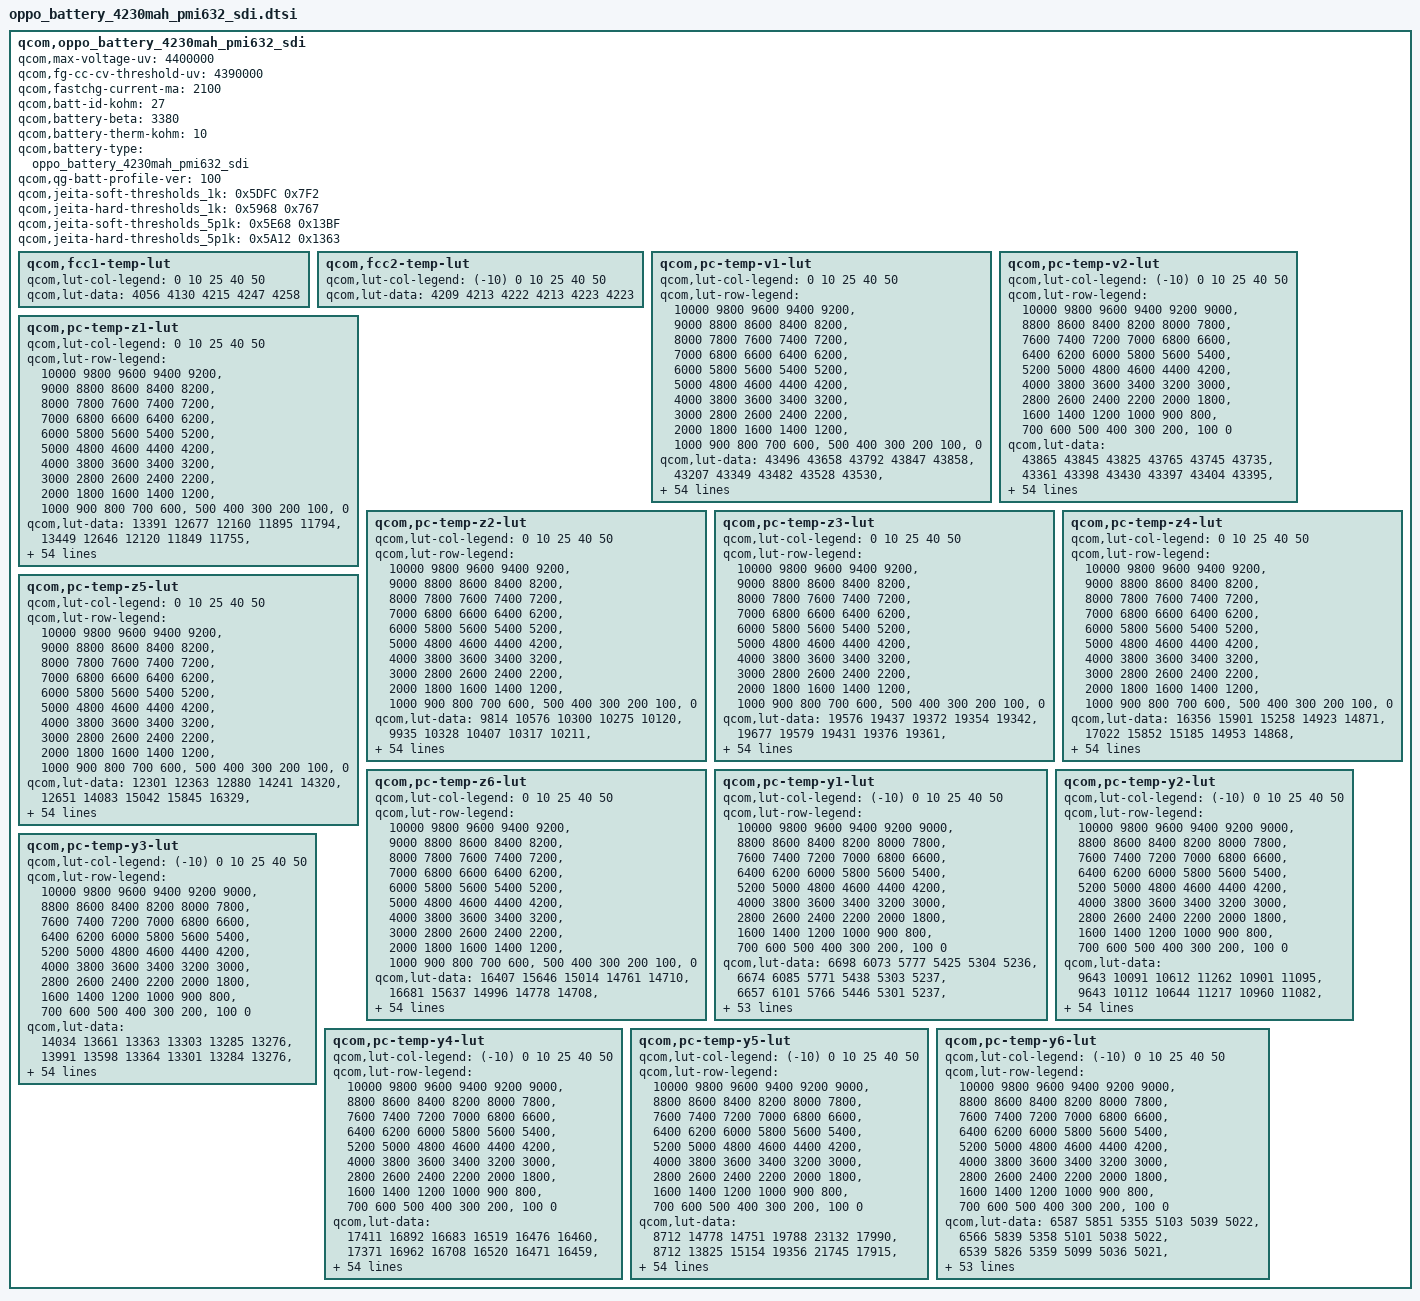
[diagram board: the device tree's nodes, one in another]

qcom,oppo_battery_4230mah_pmi632_sdi {
    qcom,max-voltage-uv = <4400000>;
    qcom,fg-cc-cv-threshold-uv = <4390000>;
    qcom,fastchg-current-ma = <2100>;
    qcom,batt-id-kohm = <27>;
    qcom,battery-beta = <3380>;
    qcom,battery-therm-kohm = <10>;
    qcom,battery-type = "oppo_battery_4230mah_pmi632_sdi";
    qcom,qg-batt-profile-ver = <100>;
    qcom,jeita-soft-thresholds_1k = <0x5DFC 0x7F2>;      //soft threshold -30  90
    qcom,jeita-hard-thresholds_1k = <0x5968 0x767>;      //hard threshold -35  95
    qcom,jeita-soft-thresholds_5p1k = <0x5E68 0x13BF>;   //soft threshold -30  90
    qcom,jeita-hard-thresholds_5p1k = <0x5A12 0x1363>;   //hard threshold -35  95

	qcom,fcc1-temp-lut {
		qcom,lut-col-legend = <0 10 25 40 50>;
		qcom,lut-data = <4056 4130 4215 4247 4258>;
	};

	qcom,fcc2-temp-lut {
		qcom,lut-col-legend = <(-10) 0 10 25 40 50>;
		qcom,lut-data = <4209 4213 4222 4213 4223 4223>;
	};

	qcom,pc-temp-v1-lut {
		qcom,lut-col-legend = <0 10 25 40 50>;
		qcom,lut-row-legend = <10000 9800 9600 9400 9200>,
			<9000 8800 8600 8400 8200>,
			<8000 7800 7600 7400 7200>,
			<7000 6800 6600 6400 6200>,
			<6000 5800 5600 5400 5200>,
			<5000 4800 4600 4400 4200>,
			<4000 3800 3600 3400 3200>,
			<3000 2800 2600 2400 2200>,
			<2000 1800 1600 1400 1200>,
			<1000 900 800 700 600>,
			<500 400 300 200 100>,
			<0>;
		qcom,lut-data = <43496 43658 43792 43847 43858>,
			<43207 43349 43482 43528 43530>,
			<42943 43079 43194 43240 43246>,
			<42695 42837 42932 42977 42983>,
			<42459 42605 42691 42738 42742>,
			<42234 42371 42458 42509 42512>,
			<42014 42143 42231 42275 42282>,
			<41799 41922 42008 42043 42054>,
			<41594 41705 41782 41816 41830>,
			<41403 41496 41554 41593 41605>,
			<41227 41305 41336 41375 41384>,
			<41036 41122 41136 41165 41170>,
			<40805 40922 40942 40962 40962>,
			<40561 40695 40739 40761 40760>,
			<40339 40468 40528 40559 40561>,
			<40130 40265 40329 40365 40369>,
			<39949 40074 40145 40183 40188>,
			<39811 39914 39974 40011 40015>,
			<39695 39788 39822 39848 39851>,
			<39577 39671 39686 39700 39700>,
			<39456 39541 39542 39548 39547>,
			<39337 39404 39377 39376 39375>,
			<39215 39246 39200 39193 39193>,
			<39092 39023 39008 39011 39013>,
			<38972 38791 38792 38820 38828>,
			<38855 38644 38632 38657 38664>,
			<38741 38539 38544 38549 38544>,
			<38632 38463 38476 38462 38445>,
			<38520 38410 38408 38379 38357>,
			<38428 38369 38342 38297 38278>,
			<38368 38331 38282 38224 38208>,
			<38321 38297 38226 38160 38142>,
			<38284 38265 38174 38105 38081>,
			<38254 38233 38129 38055 38026>,
			<38228 38204 38091 38012 37978>,
			<38202 38174 38053 37970 37929>,
			<38177 38145 38016 37925 37876>,
			<38145 38111 37977 37877 37818>,
			<38099 38057 37922 37814 37748>,
			<38035 37974 37844 37732 37660>,
			<37949 37877 37752 37636 37561>,
			<37820 37760 37641 37529 37452>,
			<37680 37623 37510 37403 37326>,
			<37531 37456 37347 37242 37164>,
			<37386 37299 37190 37092 37020>,
			<37270 37181 37077 36989 36926>,
			<37225 37143 37051 36957 36901>,
			<37191 37122 37027 36940 36879>,
			<37163 37098 37013 36921 36862>,
			<37121 37079 36981 36887 36824>,
			<36984 36940 36814 36700 36609>,
			<36576 36529 36397 36285 36188>,
			<36007 35959 35832 35723 35625>,
			<35241 35195 35061 34958 34857>,
			<34027 34002 33855 33774 33672>,
			<30000 30000 30000 30000 30000>;
	};

	qcom,pc-temp-v2-lut {
		qcom,lut-col-legend = <(-10) 0 10 25 40 50>;
		qcom,lut-row-legend = <10000 9800 9600 9400 9200 9000>,
			<8800 8600 8400 8200 8000 7800>,
			<7600 7400 7200 7000 6800 6600>,
			<6400 6200 6000 5800 5600 5400>,
			<5200 5000 4800 4600 4400 4200>,
			<4000 3800 3600 3400 3200 3000>,
			<2800 2600 2400 2200 2000 1800>,
			<1600 1400 1200 1000 900 800>,
			<700 600 500 400 300 200>,
			<100 0>;
		qcom,lut-data = <43865 43845 43825 43765 43745 43735>,
			<43361 43398 43430 43397 43404 43395>,
			<42932 43004 43079 43068 43093 43086>,
			<42595 42671 42779 42783 42817 42812>,
			<42332 42386 42523 42539 42573 42571>,
			<42080 42133 42280 42307 42339 42339>,
			<41788 41911 42038 42075 42106 42107>,
			<41506 41707 41802 41850 41878 41879>,
			<41308 41477 41572 41628 41655 41655>,
			<41174 41216 41344 41408 41436 41434>,
			<41034 40988 41130 41194 41221 41218>,
			<40857 40839 40949 40993 41010 41005>,
			<40650 40708 40775 40797 40802 40796>,
			<40376 40500 40564 40592 40600 40597>,
			<39973 40153 40302 40373 40401 40402>,
			<39625 39846 40066 40168 40212 40216>,
			<39436 39673 39899 39992 40036 40037>,
			<39291 39536 39754 39830 39868 39865>,
			<39132 39368 39585 39676 39706 39702>,
			<38958 39168 39395 39535 39556 39552>,
			<38789 38970 39201 39380 39394 39391>,
			<38618 38793 39001 39172 39194 39196>,
			<38456 38627 38805 38938 38979 38987>,
			<38343 38469 38641 38749 38793 38802>,
			<38264 38310 38499 38592 38625 38632>,
			<38198 38187 38373 38459 38483 38487>,
			<38138 38115 38261 38349 38374 38374>,
			<38084 38062 38161 38254 38280 38278>,
			<38031 38013 38072 38168 38193 38190>,
			<37982 37969 37991 38091 38112 38109>,
			<37934 37927 37925 38021 38040 38037>,
			<37884 37885 37877 37954 37975 37970>,
			<37833 37843 37838 37892 37916 37908>,
			<37780 37800 37803 37835 37855 37846>,
			<37727 37757 37773 37785 37797 37788>,
			<37671 37711 37739 37735 37731 37719>,
			<37608 37659 37701 37682 37649 37620>,
			<37542 37600 37658 37627 37557 37504>,
			<37472 37534 37598 37563 37473 37409>,
			<37396 37458 37511 37488 37396 37332>,
			<37319 37375 37410 37404 37316 37253>,
			<37241 37282 37294 37304 37223 37160>,
			<37163 37180 37168 37188 37115 37055>,
			<37089 37075 37054 37048 36974 36913>,
			<37011 36967 36947 36916 36849 36795>,
			<36926 36849 36840 36841 36795 36745>,
			<36874 36787 36784 36825 36783 36736>,
			<36815 36738 36749 36808 36767 36721>,
			<36743 36689 36698 36779 36742 36694>,
			<36649 36627 36615 36723 36676 36617>,
			<36475 36498 36452 36516 36417 36329>,
			<36138 36176 36121 36057 35939 35843>,
			<35607 35599 35550 35424 35297 35192>,
			<34805 34782 34731 34555 34410 34286>,
			<33472 33472 33449 33122 33050 32912>,
			<28768 28439 29277 28287 29008 29119>;
	};

	qcom,pc-temp-z1-lut {
		qcom,lut-col-legend = <0 10 25 40 50>;
		qcom,lut-row-legend = <10000 9800 9600 9400 9200>,
			<9000 8800 8600 8400 8200>,
			<8000 7800 7600 7400 7200>,
			<7000 6800 6600 6400 6200>,
			<6000 5800 5600 5400 5200>,
			<5000 4800 4600 4400 4200>,
			<4000 3800 3600 3400 3200>,
			<3000 2800 2600 2400 2200>,
			<2000 1800 1600 1400 1200>,
			<1000 900 800 700 600>,
			<500 400 300 200 100>,
			<0>;
		qcom,lut-data = <13391 12677 12160 11895 11794>,
			<13449 12646 12120 11849 11755>,
			<13386 12639 12092 11831 11739>,
			<13335 12637 12078 11821 11731>,
			<13317 12633 12070 11813 11725>,
			<13304 12614 12064 11808 11721>,
			<13301 12587 12056 11804 11720>,
			<13304 12578 12047 11799 11721>,
			<13306 12582 12043 11795 11720>,
			<13302 12585 12040 11793 11718>,
			<13282 12572 12038 11792 11716>,
			<13255 12547 12037 11792 11715>,
			<13204 12535 12036 11792 11714>,
			<13149 12531 12033 11791 11713>,
			<13131 12529 12027 11787 11712>,
			<13124 12525 12024 11784 11711>,
			<13120 12516 12026 11785 11712>,
			<13128 12513 12028 11787 11713>,
			<13150 12521 12029 11788 11714>,
			<13161 12531 12034 11790 11714>,
			<13163 12536 12037 11791 11715>,
			<13163 12548 12038 11791 11715>,
			<13164 12554 12040 11792 11716>,
			<13169 12552 12042 11793 11717>,
			<13175 12551 12045 11796 11718>,
			<13189 12555 12047 11798 11720>,
			<13206 12570 12048 11800 11723>,
			<13210 12581 12049 11802 11726>,
			<13205 12579 12052 11805 11730>,
			<13199 12573 12059 11809 11733>,
			<13198 12572 12066 11813 11737>,
			<13201 12572 12072 11817 11739>,
			<13209 12573 12077 11820 11742>,
			<13225 12579 12079 11823 11744>,
			<13241 12589 12079 11827 11747>,
			<13253 12595 12081 11831 11750>,
			<13273 12600 12087 11834 11753>,
			<13284 12606 12095 11837 11757>,
			<13283 12622 12102 11841 11760>,
			<13284 12651 12110 11847 11764>,
			<13293 12666 12115 11853 11767>,
			<13326 12664 12115 11857 11772>,
			<13336 12663 12115 11862 11777>,
			<13324 12673 12122 11865 11779>,
			<13307 12672 12132 11870 11783>,
			<13326 12693 12132 11873 11783>,
			<13300 12669 12131 11876 11783>,
			<13310 12678 12130 11877 11786>,
			<13284 12661 12140 11880 11789>,
			<13282 12675 12139 11885 11793>,
			<13293 12711 12146 11887 11800>,
			<13373 12696 12156 11896 11809>,
			<13339 12715 12163 11907 11819>,
			<13399 12757 12191 11927 11833>,
			<13399 12757 12191 11927 11833>,
			<13399 12757 12191 11927 11833>;
	};

	qcom,pc-temp-z2-lut {
		qcom,lut-col-legend = <0 10 25 40 50>;
		qcom,lut-row-legend = <10000 9800 9600 9400 9200>,
			<9000 8800 8600 8400 8200>,
			<8000 7800 7600 7400 7200>,
			<7000 6800 6600 6400 6200>,
			<6000 5800 5600 5400 5200>,
			<5000 4800 4600 4400 4200>,
			<4000 3800 3600 3400 3200>,
			<3000 2800 2600 2400 2200>,
			<2000 1800 1600 1400 1200>,
			<1000 900 800 700 600>,
			<500 400 300 200 100>,
			<0>;
		qcom,lut-data = <9814 10576 10300 10275 10120>,
			<9935 10328 10407 10317 10211>,
			<10076 10260 10464 10399 10292>,
			<10163 10243 10456 10505 10341>,
			<10182 10230 10408 10886 10322>,
			<10193 10214 10393 11193 10281>,
			<10196 10199 10785 10973 10240>,
			<10185 10185 11280 10491 10165>,
			<10169 10172 11196 10382 10137>,
			<10156 10161 10640 10781 10159>,
			<10144 10154 10347 11121 10185>,
			<10131 10149 10349 11269 10186>,
			<10117 10149 10354 11653 10180>,
			<10103 10168 10530 11852 10179>,
			<10089 10192 11192 11956 10195>,
			<10074 10201 11543 12023 10221>,
			<10064 10207 11080 11566 10243>,
			<10061 10216 10468 10558 10268>,
			<10060 10241 10384 10248 10283>,
			<10059 10274 10416 10281 10291>,
			<10055 10305 10452 10325 10299>,
			<10052 10338 10489 10365 10322>,
			<10054 10365 10520 10403 10364>,
			<10065 10385 10511 10414 10383>,
			<10078 10401 10454 10395 10386>,
			<10096 10410 10422 10380 10390>,
			<10119 10415 10455 10382 10467>,
			<10144 10421 10504 10385 10630>,
			<10172 10431 10518 10397 10660>,
			<10194 10442 10522 10455 10446>,
			<10202 10445 10526 10499 10248>,
			<10206 10443 10532 10472 10214>,
			<10212 10442 10538 10414 10196>,
			<10219 10448 10537 10380 10194>,
			<10228 10463 10529 10359 10212>,
			<10240 10471 10524 10349 10242>,
			<10256 10473 10541 10367 10293>,
			<10275 10476 10572 10410 10363>,
			<10297 10488 10591 10452 10412>,
			<10320 10515 10606 10507 10452>,
			<10340 10530 10618 10541 10472>,
			<10357 10531 10631 10530 10467>,
			<10322 10530 10638 10516 10461>,
			<10033 10529 10629 10523 10457>,
			<9845 10619 10663 10529 10469>,
			<9827 10658 10703 10538 10447>,
			<9873 10657 10646 10541 10448>,
			<9912 10672 10654 10552 10458>,
			<10031 10671 10609 10562 10485>,
			<10017 10584 10625 10619 10604>,
			<9982 10655 10680 10586 10472>,
			<9785 10543 10665 10427 10264>,
			<9617 10433 10609 10372 10221>,
			<9485 10165 10562 10328 10178>,
			<9485 10165 10562 10328 10178>,
			<9485 10165 10562 10328 10178>;
	};

	qcom,pc-temp-z3-lut {
		qcom,lut-col-legend = <0 10 25 40 50>;
		qcom,lut-row-legend = <10000 9800 9600 9400 9200>,
			<9000 8800 8600 8400 8200>,
			<8000 7800 7600 7400 7200>,
			<7000 6800 6600 6400 6200>,
			<6000 5800 5600 5400 5200>,
			<5000 4800 4600 4400 4200>,
			<4000 3800 3600 3400 3200>,
			<3000 2800 2600 2400 2200>,
			<2000 1800 1600 1400 1200>,
			<1000 900 800 700 600>,
			<500 400 300 200 100>,
			<0>;
		qcom,lut-data = <19576 19437 19372 19354 19342>,
			<19677 19579 19431 19376 19361>,
			<19710 19610 19469 19395 19375>,
			<19722 19616 19473 19405 19382>,
			<19706 19618 19472 19411 19385>,
			<19673 19616 19473 19414 19386>,
			<19654 19614 19485 19411 19385>,
			<19645 19610 19501 19405 19384>,
			<19639 19604 19497 19403 19382>,
			<19635 19597 19473 19407 19380>,
			<19632 19588 19453 19411 19377>,
			<19631 19577 19443 19411 19373>,
			<19634 19567 19437 19411 19368>,
			<19638 19557 19439 19410 19364>,
			<19638 19548 19450 19407 19362>,
			<19627 19540 19455 19402 19359>,
			<19612 19532 19441 19388 19356>,
			<19594 19523 19419 19366 19353>,
			<19574 19508 19409 19357 19349>,
			<19565 19496 19403 19354 19344>,
			<19571 19493 19401 19353 19341>,
			<19581 19492 19405 19355 19342>,
			<19594 19491 19411 19360 19345>,
			<19618 19499 19411 19361 19345>,
			<19633 19511 19406 19353 19339>,
			<19636 19512 19402 19346 19333>,
			<19638 19511 19401 19348 19347>,
			<19638 19509 19400 19355 19379>,
			<19637 19507 19401 19363 19389>,
			<19637 19504 19409 19380 19384>,
			<19633 19502 19416 19391 19376>,
			<19624 19501 19421 19390 19372>,
			<19616 19499 19424 19385 19368>,
			<19608 19497 19424 19381 19363>,
			<19599 19494 19420 19374 19357>,
			<19589 19492 19415 19368 19351>,
			<19578 19488 19411 19362 19345>,
			<19567 19484 19407 19357 19340>,
			<19556 19480 19403 19355 19339>,
			<19546 19477 19399 19354 19340>,
			<19542 19474 19395 19353 19341>,
			<19541 19469 19393 19351 19342>,
			<19522 19465 19390 19350 19344>,
			<19409 19461 19386 19350 19347>,
			<19292 19440 19379 19347 19345>,
			<19266 19427 19376 19341 19339>,
			<19265 19427 19368 19341 19328>,
			<19264 19408 19369 19334 19327>,
			<19263 19397 19357 19331 19323>,
			<19263 19266 19353 19326 19311>,
			<19263 19307 19349 19335 19331>,
			<19266 19301 19351 19346 19345>,
			<19269 19267 19351 19349 19344>,
			<19274 19267 19347 19352 19348>,
			<19274 19267 19347 19352 19348>,
			<19274 19267 19347 19352 19348>;
	};

	qcom,pc-temp-z4-lut {
		qcom,lut-col-legend = <0 10 25 40 50>;
		qcom,lut-row-legend = <10000 9800 9600 9400 9200>,
			<9000 8800 8600 8400 8200>,
			<8000 7800 7600 7400 7200>,
			<7000 6800 6600 6400 6200>,
			<6000 5800 5600 5400 5200>,
			<5000 4800 4600 4400 4200>,
			<4000 3800 3600 3400 3200>,
			<3000 2800 2600 2400 2200>,
			<2000 1800 1600 1400 1200>,
			<1000 900 800 700 600>,
			<500 400 300 200 100>,
			<0>;
		qcom,lut-data = <16356 15901 15258 14923 14871>,
			<17022 15852 15185 14953 14868>,
			<16698 15726 15111 14907 14846>,
			<16331 15473 15035 14862 14822>,
			<16080 15252 14958 14813 14800>,
			<15858 15128 14884 14777 14779>,
			<15684 15033 14802 14763 14760>,
			<15545 14962 14739 14751 14743>,
			<15430 14907 14733 14740 14730>,
			<15330 14863 14735 14714 14720>,
			<15244 14826 14736 14690 14713>,
			<15171 14794 14732 14676 14708>,
			<15105 14773 14722 14659 14704>,
			<15050 14758 14705 14649 14700>,
			<15012 14747 14674 14644 14693>,
			<14986 14740 14659 14641 14687>,
			<14962 14736 14671 14650 14680>,
			<14938 14730 14685 14670 14674>,
			<14915 14717 14686 14676 14669>,
			<14893 14704 14679 14669 14663>,
			<14866 14702 14676 14663 14660>,
			<14838 14701 14683 14670 14667>,
			<14808 14701 14700 14693 14690>,
			<14772 14753 14734 14722 14719>,
			<14755 14828 14803 14774 14763>,
			<14754 14847 14840 14809 14794>,
			<14756 14851 14830 14801 14775>,
			<14763 14853 14811 14778 14727>,
			<14781 14842 14792 14755 14704>,
			<14795 14818 14771 14727 14698>,
			<14793 14799 14752 14705 14693>,
			<14789 14783 14737 14696 14687>,
			<14783 14769 14725 14691 14681>,
			<14774 14755 14718 14687 14677>,
			<14763 14742 14713 14684 14673>,
			<14753 14732 14710 14682 14672>,
			<14744 14721 14709 14684 14673>,
			<14735 14714 14709 14687 14678>,
			<14727 14713 14710 14692 14683>,
			<14719 14713 14713 14698 14691>,
			<14715 14713 14715 14701 14696>,
			<14713 14709 14708 14695 14689>,
			<14728 14703 14698 14687 14680>,
			<14835 14698 14694 14686 14680>,
			<14899 14682 14678 14678 14673>,
			<14908 14671 14666 14667 14661>,
			<14904 14665 14663 14660 14662>,
			<14897 14670 14651 14652 14649>,
			<14890 14674 14647 14635 14633>,
			<14883 14810 14643 14628 14629>,
			<14881 14766 14658 14641 14640>,
			<14902 14791 14671 14645 14642>,
			<14918 14837 14672 14645 14645>,
			<14929 14843 14678 14643 14642>,
			<14929 14843 14678 14643 14642>,
			<14929 14843 14678 14643 14642>;
	};

	qcom,pc-temp-z5-lut {
		qcom,lut-col-legend = <0 10 25 40 50>;
		qcom,lut-row-legend = <10000 9800 9600 9400 9200>,
			<9000 8800 8600 8400 8200>,
			<8000 7800 7600 7400 7200>,
			<7000 6800 6600 6400 6200>,
			<6000 5800 5600 5400 5200>,
			<5000 4800 4600 4400 4200>,
			<4000 3800 3600 3400 3200>,
			<3000 2800 2600 2400 2200>,
			<2000 1800 1600 1400 1200>,
			<1000 900 800 700 600>,
			<500 400 300 200 100>,
			<0>;
		qcom,lut-data = <12301 12363 12880 14241 14320>,
			<12651 14083 15042 15845 16329>,
			<13190 15039 16673 17599 18080>,
			<13659 15600 17545 18813 19182>,
			<13937 16165 18042 19737 19833>,
			<14164 16900 18818 20317 20331>,
			<14408 17716 21458 20540 20673>,
			<14672 18581 24261 20831 21043>,
			<14940 19532 24527 21526 21537>,
			<15197 20481 24072 25248 22460>,
			<15444 21323 23815 28587 23229>,
			<15760 22146 23881 29916 23145>,
			<16401 23292 24048 32243 22729>,
			<17067 25603 25759 33985 22603>,
			<17190 27449 31555 36015 23473>,
			<17114 27412 34598 37403 24642>,
			<16997 26932 31516 33887 25443>,
			<16688 26710 27481 26093 26258>,
			<16172 26763 27155 23790 26792>,
			<15992 26888 28502 25107 27430>,
			<16607 27837 30530 27094 28185>,
			<17764 31459 35557 29883 29150>,
			<19884 36189 40914 33145 30382>,
			<24418 44578 40324 33173 30241>,
			<29284 52911 34086 25959 23710>,
			<34064 53190 28576 19593 17689>,
			<38864 47574 25291 18698 19364>,
			<42991 42275 23036 18242 23748>,
			<47143 39438 22946 18613 25378>,
			<49506 37298 24133 22548 25369>,
			<48493 36415 25894 27019 25394>,
			<45698 35943 29326 29809 26380>,
			<43189 35716 33692 32116 28295>,
			<40930 36290 36768 33701 29827>,
			<38616 37736 39382 35080 31222>,
			<36384 38816 40697 35783 31994>,
			<34094 39527 40913 34999 31448>,
			<32348 40118 40915 33169 30078>,
			<30986 40795 40090 31546 28759>,
			<29912 41679 36620 30045 27265>,
			<30087 41951 33365 28499 26264>,
			<32507 39328 31534 26495 25990>,
			<32318 36821 30089 25089 25872>,
			<23446 35720 28699 24984 26962>,
			<13840 34306 29958 24780 27280>,
			<11602 32505 31300 23265 24535>,
			<11572 33062 27046 23856 20077>,
			<11538 24528 29379 22330 21428>,
			<11477 22711 24523 25345 24311>,
			<11478 11659 24111 26475 21914>,
			<11520 13546 20814 25047 26160>,
			<11574 12928 18341 22924 25079>,
			<11455 11622 17685 22312 22396>,
			<11357 11492 16522 22048 21883>,
			<11357 11492 16522 22048 21883>,
			<11357 11492 16522 22048 21883>;
	};

	qcom,pc-temp-z6-lut {
		qcom,lut-col-legend = <0 10 25 40 50>;
		qcom,lut-row-legend = <10000 9800 9600 9400 9200>,
			<9000 8800 8600 8400 8200>,
			<8000 7800 7600 7400 7200>,
			<7000 6800 6600 6400 6200>,
			<6000 5800 5600 5400 5200>,
			<5000 4800 4600 4400 4200>,
			<4000 3800 3600 3400 3200>,
			<3000 2800 2600 2400 2200>,
			<2000 1800 1600 1400 1200>,
			<1000 900 800 700 600>,
			<500 400 300 200 100>,
			<0>;
		qcom,lut-data = <16407 15646 15014 14761 14710>,
			<16681 15637 14996 14778 14708>,
			<16492 15595 14971 14762 14704>,
			<16272 15457 14939 14747 14699>,
			<16108 15327 14896 14730 14691>,
			<15958 15253 14859 14715 14682>,
			<15841 15194 14832 14704 14674>,
			<15749 15146 14809 14695 14665>,
			<15673 15108 14792 14687 14659>,
			<15609 15075 14779 14679 14653>,
			<15556 15046 14768 14671 14648>,
			<15506 15020 14760 14664 14643>,
			<15453 14997 14753 14658 14638>,
			<15404 14976 14746 14653 14633>,
			<15366 14959 14739 14648 14629>,
			<15334 14951 14733 14644 14625>,
			<15308 14945 14727 14639 14620>,
			<15284 14938 14722 14634 14615>,
			<15264 14926 14718 14630 14611>,
			<15256 14917 14713 14626 14606>,
			<15253 14917 14711 14623 14602>,
			<15251 14918 14716 14627 14606>,
			<15252 14920 14727 14639 14618>,
			<15254 14948 14743 14653 14630>,
			<15257 14986 14771 14672 14646>,
			<15262 14997 14785 14684 14657>,
			<15267 14999 14781 14682 14657>,
			<15275 15001 14773 14677 14655>,
			<15285 14996 14768 14673 14652>,
			<15293 14987 14764 14670 14646>,
			<15291 14980 14760 14667 14641>,
			<15287 14974 14758 14663 14636>,
			<15283 14969 14756 14659 14632>,
			<15279 14964 14753 14655 14628>,
			<15274 14960 14750 14651 14623>,
			<15269 14957 14748 14647 14620>,
			<15263 14954 14747 14646 14618>,
			<15259 14953 14747 14645 14618>,
			<15258 14954 14747 14645 14618>,
			<15257 14958 14748 14648 14622>,
			<15258 14960 14748 14650 14625>,
			<15265 14961 14746 14648 14623>,
			<15269 14962 14744 14644 14621>,
			<15269 14965 14742 14645 14623>,
			<15252 14958 14736 14641 14620>,
			<15246 14952 14732 14634 14612>,
			<15245 14951 14727 14632 14607>,
			<15242 14944 14723 14624 14601>,
			<15241 14942 14716 14616 14592>,
			<15242 14938 14714 14611 14584>,
			<15250 14946 14723 14623 14601>,
			<15270 14963 14734 14634 14612>,
			<15291 14977 14739 14638 14616>,
			<15319 14995 14747 14643 14620>,
			<15319 14995 14747 14643 14620>,
			<15319 14995 14747 14643 14620>;
	};

	qcom,pc-temp-y1-lut {
		qcom,lut-col-legend = <(-10) 0 10 25 40 50>;
		qcom,lut-row-legend = <10000 9800 9600 9400 9200 9000>,
			<8800 8600 8400 8200 8000 7800>,
			<7600 7400 7200 7000 6800 6600>,
			<6400 6200 6000 5800 5600 5400>,
			<5200 5000 4800 4600 4400 4200>,
			<4000 3800 3600 3400 3200 3000>,
			<2800 2600 2400 2200 2000 1800>,
			<1600 1400 1200 1000 900 800>,
			<700 600 500 400 300 200>,
			<100 0>;
		qcom,lut-data = <6698 6073 5777 5425 5304 5236>,
			<6674 6085 5771 5438 5303 5237>,
			<6657 6101 5766 5446 5301 5237>,
			<6646 6118 5761 5451 5299 5237>,
			<6640 6131 5756 5454 5298 5237>,
			<6638 6137 5753 5455 5296 5237>,
			<6645 6137 5749 5452 5294 5235>,
			<6655 6135 5747 5447 5292 5233>,
			<6656 6135 5746 5446 5290 5232>,
			<6647 6136 5743 5446 5289 5231>,
			<6640 6135 5742 5445 5287 5230>,
			<6638 6129 5746 5444 5286 5229>,
			<6634 6121 5753 5443 5284 5227>,
			<6639 6122 5755 5442 5283 5226>,
			<6656 6140 5756 5442 5281 5225>,
			<6668 6155 5757 5442 5280 5225>,
			<6669 6158 5760 5442 5280 5225>,
			<6670 6159 5763 5442 5280 5224>,
			<6665 6159 5764 5443 5280 5224>,
			<6637 6154 5762 5446 5280 5224>,
			<6615 6149 5760 5448 5280 5225>,
			<6627 6146 5758 5447 5280 5225>,
			<6651 6143 5755 5446 5280 5225>,
			<6657 6141 5755 5446 5280 5225>,
			<6651 6135 5759 5448 5282 5227>,
			<6645 6130 5764 5450 5284 5228>,
			<6643 6130 5773 5453 5285 5229>,
			<6641 6134 5784 5456 5287 5229>,
			<6638 6136 5785 5459 5288 5231>,
			<6632 6139 5774 5461 5290 5233>,
			<6628 6140 5766 5463 5292 5235>,
			<6632 6137 5770 5466 5295 5237>,
			<6638 6131 5777 5468 5298 5240>,
			<6638 6127 5781 5469 5301 5242>,
			<6631 6131 5782 5469 5304 5244>,
			<6625 6136 5782 5470 5307 5246>,
			<6626 6139 5783 5473 5310 5249>,
			<6627 6145 5787 5478 5312 5251>,
			<6629 6146 5787 5482 5313 5253>,
			<6631 6146 5785 5485 5315 5255>,
			<6634 6145 5784 5488 5316 5256>,
			<6638 6141 5791 5488 5318 5258>,
			<6633 6134 5798 5489 5321 5260>,
			<6615 6138 5788 5494 5325 5263>,
			<6613 6138 5790 5496 5328 5267>,
			<6624 6145 5803 5497 5334 5270>,
			<6617 6164 5789 5504 5335 5271>,
			<6645 6167 5812 5504 5335 5271>,
			<6669 6155 5797 5508 5336 5271>,
			<6641 6184 5803 5505 5338 5273>,
			<6634 6183 5808 5507 5337 5275>,
			<6656 6163 5812 5515 5348 5281>,
			<6648 6169 5824 5536 5357 5288>,
			<6726 6226 5856 5556 5368 5299>,
			<6726 6226 5856 5556 5368 5299>,
			<6726 6226 5856 5556 5368 5299>;
	};

	qcom,pc-temp-y2-lut {
		qcom,lut-col-legend = <(-10) 0 10 25 40 50>;
		qcom,lut-row-legend = <10000 9800 9600 9400 9200 9000>,
			<8800 8600 8400 8200 8000 7800>,
			<7600 7400 7200 7000 6800 6600>,
			<6400 6200 6000 5800 5600 5400>,
			<5200 5000 4800 4600 4400 4200>,
			<4000 3800 3600 3400 3200 3000>,
			<2800 2600 2400 2200 2000 1800>,
			<1600 1400 1200 1000 900 800>,
			<700 600 500 400 300 200>,
			<100 0>;
		qcom,lut-data = <9643 10091 10612 11262 10901 11095>,
			<9643 10112 10644 11217 10960 11082>,
			<9727 10134 10674 11142 10996 11063>,
			<9877 10156 10698 11059 11015 11040>,
			<9951 10178 10715 10989 11023 11016>,
			<9970 10200 10721 10955 11024 10992>,
			<9879 10218 10717 10948 11005 10967>,
			<9728 10239 10706 10945 10969 10940>,
			<9687 10310 10694 10943 10943 10918>,
			<9680 10547 10669 10942 10921 10896>,
			<9678 10703 10655 10940 10900 10882>,
			<9679 10653 10718 10917 10876 10878>,
			<9680 10568 10826 10880 10855 10877>,
			<9680 10557 10868 10877 10852 10868>,
			<9674 10611 10881 10913 10857 10845>,
			<9670 10682 10897 10960 10866 10831>,
			<9670 10766 10944 10999 10906 10836>,
			<9669 10854 11006 11043 10978 10846>,
			<9669 10895 11037 11105 11046 10856>,
			<9668 10918 11056 11206 11121 10880>,
			<9668 10928 11064 11267 11163 10911>,
			<9667 10591 11054 11247 11149 10970>,
			<9666 9965 11037 11209 11121 11049>,
			<9665 9762 11040 11201 11123 11100>,
			<9665 9723 11075 11217 11168 11146>,
			<9664 9705 11101 11239 11203 11170>,
			<9664 9699 11096 11258 11210 11162>,
			<9663 9695 11089 11279 11215 11149>,
			<9662 9691 11088 11307 11223 11154>,
			<9662 9686 11093 11355 11261 11206>,
			<9661 9681 11097 11392 11301 11257>,
			<9661 9678 11079 11405 11342 11280>,
			<9660 9674 11038 11415 11386 11298>,
			<9660 9672 11000 11416 11400 11306>,
			<9659 9669 10964 11406 11401 11312>,
			<9659 9667 10924 11392 11396 11313>,
			<9659 9665 10884 11376 11367 11293>,
			<9659 9663 10833 11353 11323 11259>,
			<9658 9661 10694 11329 11308 11246>,
			<9658 9660 10243 11304 11307 11246>,
			<9658 9659 9874 11273 11304 11243>,
			<9658 9658 9763 11210 11273 11206>,
			<9658 9658 9706 11124 11230 11166>,
			<9657 9657 9688 11077 11236 11179>,
			<9657 9657 9678 10981 11210 11143>,
			<9657 9657 9677 10902 11146 11049>,
			<9657 9657 9675 10932 11077 10955>,
			<9657 9657 9676 10931 11068 10928>,
			<9657 9657 9675 10959 11098 10904>,
			<9657 9657 9674 10949 11115 10958>,
			<9656 9656 9673 10883 11041 10923>,
			<9656 9656 9669 10773 10948 10863>,
			<9656 9656 9665 10679 10910 10758>,
			<9655 9655 9662 10589 10808 10637>,
			<9655 9655 9662 10589 10808 10637>,
			<9655 9655 9662 10589 10808 10637>;
	};

	qcom,pc-temp-y3-lut {
		qcom,lut-col-legend = <(-10) 0 10 25 40 50>;
		qcom,lut-row-legend = <10000 9800 9600 9400 9200 9000>,
			<8800 8600 8400 8200 8000 7800>,
			<7600 7400 7200 7000 6800 6600>,
			<6400 6200 6000 5800 5600 5400>,
			<5200 5000 4800 4600 4400 4200>,
			<4000 3800 3600 3400 3200 3000>,
			<2800 2600 2400 2200 2000 1800>,
			<1600 1400 1200 1000 900 800>,
			<700 600 500 400 300 200>,
			<100 0>;
		qcom,lut-data = <14034 13661 13363 13303 13285 13276>,
			<13991 13598 13364 13301 13284 13276>,
			<13949 13557 13366 13299 13283 13276>,
			<13908 13534 13367 13299 13282 13276>,
			<13868 13524 13369 13298 13281 13276>,
			<13829 13522 13370 13298 13280 13276>,
			<13792 13538 13370 13299 13280 13277>,
			<13756 13564 13371 13300 13280 13278>,
			<13714 13556 13373 13302 13280 13279>,
			<13658 13483 13380 13302 13283 13280>,
			<13628 13432 13383 13303 13285 13280>,
			<13634 13435 13382 13305 13286 13280>,
			<13644 13442 13377 13307 13286 13280>,
			<13635 13442 13371 13307 13286 13280>,
			<13565 13432 13359 13307 13286 13282>,
			<13514 13420 13352 13307 13286 13284>,
			<13515 13412 13351 13307 13288 13284>,
			<13520 13403 13350 13306 13290 13283>,
			<13524 13392 13348 13305 13291 13284>,
			<13529 13374 13342 13305 13291 13285>,
			<13532 13364 13335 13305 13291 13286>,
			<13521 13366 13330 13302 13289 13285>,
			<13502 13370 13325 13298 13286 13283>,
			<13498 13366 13322 13294 13283 13280>,
			<13510 13337 13319 13291 13279 13277>,
			<13529 13314 13316 13289 13278 13275>,
			<13549 13315 13313 13288 13278 13275>,
			<13573 13322 13311 13287 13279 13275>,
			<13600 13330 13309 13287 13279 13275>,
			<13631 13346 13307 13288 13278 13276>,
			<13664 13365 13307 13289 13278 13276>,
			<13699 13383 13307 13289 13278 13276>,
			<13737 13402 13308 13288 13279 13275>,
			<13778 13425 13309 13288 13279 13275>,
			<13823 13453 13314 13288 13279 13276>,
			<13871 13487 13318 13288 13279 13277>,
			<13920 13527 13322 13289 13278 13276>,
			<13973 13574 13325 13290 13278 13274>,
			<14024 13628 13329 13290 13278 13274>,
			<14076 13689 13334 13291 13278 13276>,
			<14128 13757 13340 13291 13278 13277>,
			<14180 13829 13348 13291 13279 13278>,
			<14235 13905 13358 13292 13279 13278>,
			<14295 13981 13380 13293 13278 13276>,
			<14360 14054 13414 13294 13277 13275>,
			<14386 14055 13425 13295 13280 13278>,
			<14402 14072 13445 13298 13283 13282>,
			<14470 14123 13484 13302 13285 13284>,
			<14538 14166 13508 13307 13290 13285>,
			<14621 14204 13528 13314 13291 13286>,
			<14708 14241 13553 13313 13287 13283>,
			<14803 14286 13580 13312 13287 13284>,
			<14938 14396 13630 13318 13290 13287>,
			<15119 14578 13763 13331 13296 13291>,
			<15119 14578 13763 13331 13296 13291>,
			<15119 14578 13763 13331 13296 13291>;
	};

	qcom,pc-temp-y4-lut {
		qcom,lut-col-legend = <(-10) 0 10 25 40 50>;
		qcom,lut-row-legend = <10000 9800 9600 9400 9200 9000>,
			<8800 8600 8400 8200 8000 7800>,
			<7600 7400 7200 7000 6800 6600>,
			<6400 6200 6000 5800 5600 5400>,
			<5200 5000 4800 4600 4400 4200>,
			<4000 3800 3600 3400 3200 3000>,
			<2800 2600 2400 2200 2000 1800>,
			<1600 1400 1200 1000 900 800>,
			<700 600 500 400 300 200>,
			<100 0>;
		qcom,lut-data = <17411 16892 16683 16519 16476 16460>,
			<17371 16962 16708 16520 16471 16459>,
			<17347 17027 16737 16521 16467 16458>,
			<17335 17080 16764 16521 16464 16456>,
			<17330 17117 16784 16520 16463 16455>,
			<17330 17131 16792 16520 16462 16454>,
			<17352 17115 16789 16518 16463 16454>,
			<17405 17091 16782 16517 16465 16454>,
			<17485 17101 16771 16517 16466 16454>,
			<17641 17195 16750 16519 16466 16455>,
			<17738 17285 16738 16522 16466 16456>,
			<17681 17333 16788 16526 16469 16459>,
			<17548 17368 16869 16533 16474 16463>,
			<17399 17337 16879 16540 16479 16467>,
			<17194 17108 16839 16548 16486 16470>,
			<17049 16944 16812 16558 16494 16474>,
			<17011 16956 16828 16575 16501 16480>,
			<16988 16980 16854 16599 16510 16488>,
			<16948 16978 16855 16628 16525 16500>,
			<16876 16921 16824 16670 16554 16520>,
			<16809 16851 16781 16694 16572 16532>,
			<16760 16792 16722 16655 16560 16527>,
			<16723 16735 16653 16576 16534 16515>,
			<16711 16690 16613 16529 16508 16499>,
			<16707 16650 16587 16499 16476 16471>,
			<16706 16629 16567 16484 16458 16455>,
			<16706 16631 16552 16484 16459 16455>,
			<16708 16637 16539 16485 16461 16456>,
			<16711 16639 16525 16487 16464 16458>,
			<16716 16640 16508 16492 16469 16463>,
			<16722 16642 16498 16498 16477 16470>,
			<16727 16649 16503 16501 16487 16478>,
			<16732 16660 16516 16504 16498 16488>,
			<16738 16671 16529 16504 16503 16496>,
			<16744 16680 16547 16504 16506 16504>,
			<16749 16689 16567 16504 16507 16508>,
			<16753 16701 16589 16502 16493 16492>,
			<16755 16713 16612 16499 16469 16466>,
			<16758 16724 16627 16498 16464 16460>,
			<16761 16734 16638 16496 16464 16461>,
			<16765 16741 16646 16495 16465 16463>,
			<16774 16747 16651 16502 16468 16466>,
			<16789 16750 16657 16512 16471 16468>,
			<16812 16758 16673 16514 16466 16460>,
			<16841 16773 16708 16517 16459 16450>,
			<16833 16766 16723 16519 16461 16453>,
			<16823 16767 16757 16527 16472 16469>,
			<16853 16809 16820 16549 16492 16497>,
			<16876 16866 16892 16579 16524 16536>,
			<16899 16939 16969 16621 16553 16549>,
			<16909 16984 17029 16603 16499 16480>,
			<16897 16947 17020 16569 16479 16466>,
			<16880 16895 16991 16587 16490 16471>,
			<16892 16889 17061 16630 16533 16505>,
			<16892 16889 17061 16630 16533 16505>,
			<16892 16889 17061 16630 16533 16505>;
	};

	qcom,pc-temp-y5-lut {
		qcom,lut-col-legend = <(-10) 0 10 25 40 50>;
		qcom,lut-row-legend = <10000 9800 9600 9400 9200 9000>,
			<8800 8600 8400 8200 8000 7800>,
			<7600 7400 7200 7000 6800 6600>,
			<6400 6200 6000 5800 5600 5400>,
			<5200 5000 4800 4600 4400 4200>,
			<4000 3800 3600 3400 3200 3000>,
			<2800 2600 2400 2200 2000 1800>,
			<1600 1400 1200 1000 900 800>,
			<700 600 500 400 300 200>,
			<100 0>;
		qcom,lut-data = <8712 14778 14751 19788 23132 17990>,
			<8712 13825 15154 19356 21745 17915>,
			<10974 13399 15712 18703 20278 17786>,
			<12944 13390 16301 18007 18867 17644>,
			<14178 13688 16797 17444 17640 17529>,
			<14615 14184 17079 17191 16733 17481>,
			<13865 15799 17179 17211 16001 17496>,
			<12642 17900 17257 17262 15452 17510>,
			<12430 17805 17460 17209 15564 17475>,
			<12846 14799 18060 16915 16646 17351>,
			<13561 12718 18431 16624 17360 17158>,
			<16130 14725 17394 16312 16971 16476>,
			<19719 18110 15739 15955 16216 15578>,
			<19891 18714 15493 15829 15623 15479>,
			<15780 17771 16078 15537 15006 15905>,
			<12750 17095 16738 15221 14687 16189>,
			<13420 17717 17196 14878 14874 15672>,
			<14918 18862 17653 14508 15181 14834>,
			<16030 19310 18296 14542 15224 14666>,
			<16984 19437 19258 15458 15086 14722>,
			<17488 19583 19963 16753 14989 14827>,
			<16017 20033 20272 18726 16694 16284>,
			<13186 20607 20492 20929 19479 18547>,
			<12300 20138 20571 21262 19923 19012>,
			<12225 15858 20535 20211 19100 18846>,
			<12216 12499 20559 19290 18542 18639>,
			<12263 12353 20909 19004 18707 18178>,
			<12354 12299 21375 18803 18973 17496>,
			<12432 12323 21284 18878 18885 17199>,
			<12549 12565 20016 19740 18044 17095>,
			<12681 12799 18726 20589 17457 16981>,
			<12793 12874 17940 21022 17580 16633>,
			<12899 12925 17347 21422 17889 16215>,
			<13002 13041 17351 21654 18333 16375>,
			<13123 13361 18066 21851 19213 17890>,
			<13199 13606 18763 21968 19984 18977>,
			<13184 13622 19140 21968 20487 18793>,
			<13143 13615 19413 21921 20921 18453>,
			<13102 13606 19250 21782 20877 18529>,
			<12961 13571 17797 21120 20175 19488>,
			<12823 13517 16150 20160 19552 20167>,
			<12686 13382 14754 18796 19320 20073>,
			<12532 13212 13703 17550 19151 19833>,
			<12594 13177 13476 17517 18638 19248>,
			<12698 13201 13372 17197 17809 18363>,
			<12975 13123 13171 16694 17364 17551>,
			<12973 13203 13232 16670 17747 18204>,
			<12976 13577 14182 16796 17251 16864>,
			<13249 14121 14382 16633 17165 15776>,
			<14076 14603 14534 16900 16525 15357>,
			<14353 14991 14904 17123 17190 17203>,
			<13667 14666 14968 17716 18655 19316>,
			<12980 13137 13950 17934 19239 19919>,
			<12546 12451 12475 18653 21898 22352>,
			<12546 12451 12475 18653 21898 22352>,
			<12546 12451 12475 18653 21898 22352>;
	};

	qcom,pc-temp-y6-lut {
		qcom,lut-col-legend = <(-10) 0 10 25 40 50>;
		qcom,lut-row-legend = <10000 9800 9600 9400 9200 9000>,
			<8800 8600 8400 8200 8000 7800>,
			<7600 7400 7200 7000 6800 6600>,
			<6400 6200 6000 5800 5600 5400>,
			<5200 5000 4800 4600 4400 4200>,
			<4000 3800 3600 3400 3200 3000>,
			<2800 2600 2400 2200 2000 1800>,
			<1600 1400 1200 1000 900 800>,
			<700 600 500 400 300 200>,
			<100 0>;
		qcom,lut-data = <6587 5851 5355 5103 5039 5022>,
			<6566 5839 5358 5101 5038 5022>,
			<6539 5826 5359 5099 5036 5021>,
			<6506 5813 5359 5098 5035 5021>,
			<6469 5802 5358 5096 5033 5021>,
			<6427 5795 5357 5095 5033 5020>,
			<6370 5792 5351 5095 5033 5021>,
			<6314 5789 5343 5094 5033 5021>,
			<6297 5782 5336 5094 5033 5022>,
			<6294 5758 5329 5095 5035 5022>,
			<6289 5742 5326 5095 5036 5023>,
			<6274 5750 5335 5097 5037 5024>,
			<6245 5764 5349 5100 5039 5025>,
			<6197 5756 5348 5102 5040 5026>,
			<6098 5687 5327 5103 5042 5028>,
			<6031 5637 5313 5106 5044 5031>,
			<6025 5636 5316 5110 5047 5033>,
			<6022 5637 5323 5117 5051 5035>,
			<6016 5634 5322 5124 5057 5038>,
			<6002 5612 5309 5135 5065 5045>,
			<5988 5588 5291 5142 5069 5049>,
			<5974 5573 5271 5129 5065 5047>,
			<5961 5560 5248 5103 5054 5041>,
			<5960 5547 5236 5087 5044 5034>,
			<5972 5534 5229 5077 5033 5024>,
			<5989 5527 5225 5072 5027 5018>,
			<6007 5536 5222 5072 5027 5018>,
			<6029 5557 5221 5072 5028 5018>,
			<6053 5579 5220 5073 5029 5019>,
			<6080 5603 5221 5076 5031 5021>,
			<6109 5630 5222 5079 5033 5023>,
			<6140 5659 5227 5081 5037 5026>,
			<6172 5691 5240 5083 5040 5028>,
			<6206 5726 5254 5084 5042 5031>,
			<6243 5765 5272 5085 5043 5034>,
			<6281 5808 5293 5086 5044 5036>,
			<6320 5852 5316 5088 5040 5031>,
			<6360 5900 5341 5089 5033 5022>,
			<6400 5951 5366 5090 5032 5021>,
			<6441 6006 5390 5092 5033 5022>,
			<6482 6065 5418 5094 5034 5024>,
			<6524 6126 5449 5099 5035 5026>,
			<6569 6187 5487 5105 5037 5027>,
			<6622 6250 5540 5110 5035 5023>,
			<6681 6312 5610 5117 5033 5021>,
			<6704 6313 5627 5122 5037 5024>,
			<6716 6328 5655 5128 5043 5032>,
			<6774 6379 5705 5141 5050 5041>,
			<6837 6428 5743 5156 5062 5054>,
			<6908 6480 5785 5175 5071 5058>,
			<6981 6525 5827 5172 5054 5036>,
			<7057 6550 5861 5167 5049 5034>,
			<7165 6621 5916 5191 5057 5039>,
			<7323 6764 6070 5230 5076 5053>,
			<7323 6764 6070 5230 5076 5053>,
			<7323 6764 6070 5230 5076 5053>;
	};

};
